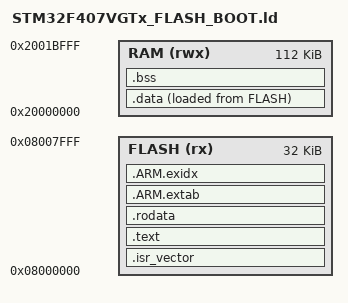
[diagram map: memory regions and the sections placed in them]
/*
 * STM32F407VG Bootloader Linker Script
 * ROM: 0x08000000, 32KB
 * RAM: 0x20000000, 112KB
 */

MEMORY
{
    FLASH (rx)  : ORIGIN = 0x08000000, LENGTH = 32K
    RAM   (rwx) : ORIGIN = 0x20000000, LENGTH = 112K
}

_estack = ORIGIN(RAM) + LENGTH(RAM);

SECTIONS
{
    .isr_vector :
    {
        . = ALIGN(4);
        KEEP(*(.isr_vector))
        . = ALIGN(4);
    } >FLASH

    .text :
    {
        . = ALIGN(4);
        *(.text)
        *(.text*)
        *(.glue_7)
        *(.glue_7t)
        *(.eh_frame)
        KEEP(*(.init))
        KEEP(*(.fini))
        . = ALIGN(4);
        _etext = .;
    } >FLASH

    .rodata :
    {
        . = ALIGN(4);
        *(.rodata)
        *(.rodata*)
        . = ALIGN(4);
    } >FLASH

    .ARM.extab :
    {
        *(.ARM.extab* .gnu.linkonce.armextab.*)
    } >FLASH

    .ARM.exidx :
    {
        *(.ARM.exidx* .gnu.linkonce.armexidx.*)
    } >FLASH

    _sidata = LOADADDR(.data);

    .data :
    {
        . = ALIGN(4);
        _sdata = .;
        *(.data)
        *(.data*)
        . = ALIGN(4);
        _edata = .;
    } >RAM AT>FLASH

    .bss :
    {
        . = ALIGN(4);
        _sbss = .;
        *(.bss)
        *(.bss*)
        *(COMMON)
        . = ALIGN(4);
        _ebss = .;
    } >RAM

    . = ALIGN(8);
}
